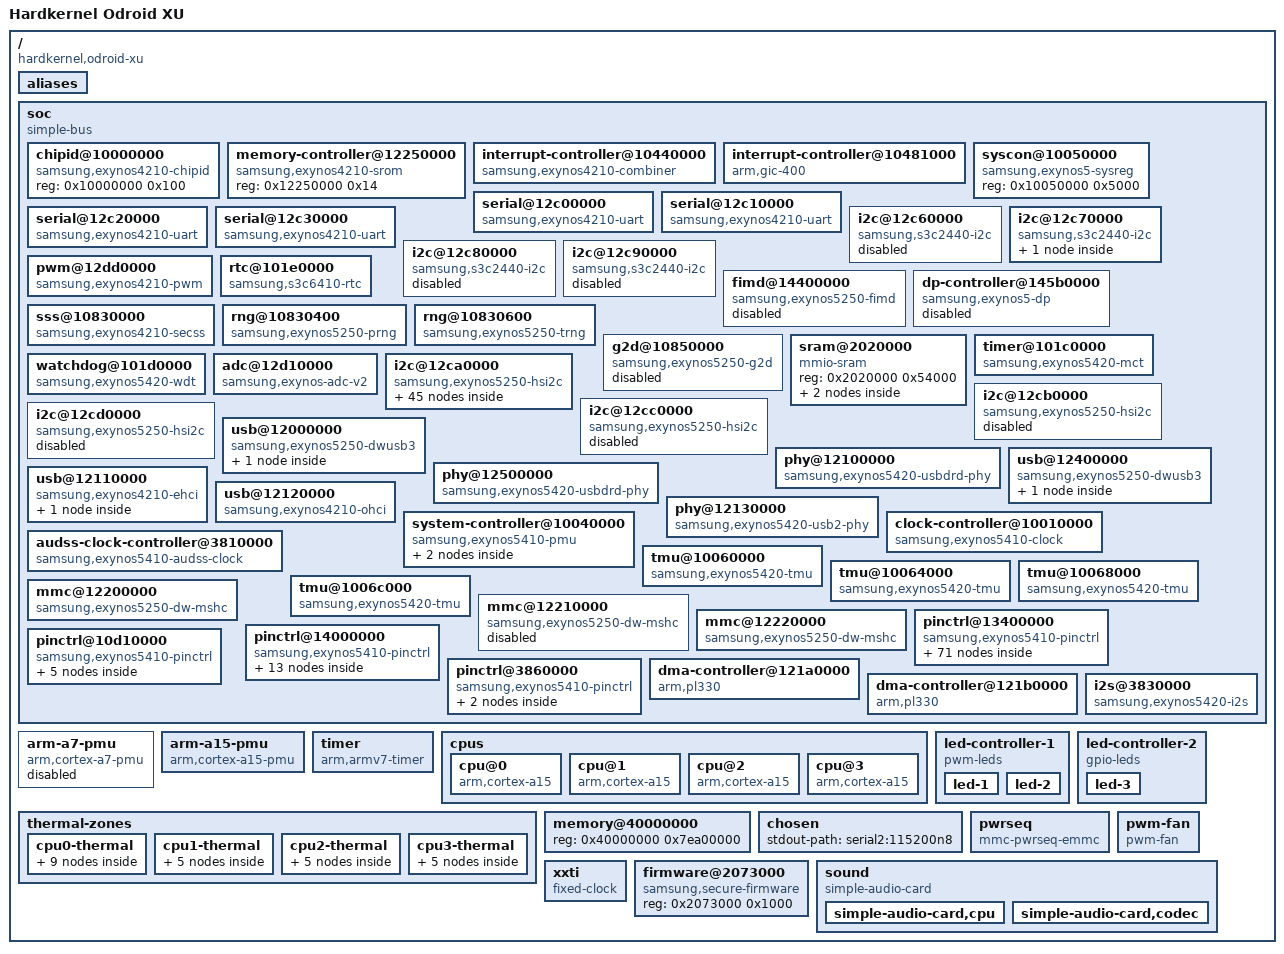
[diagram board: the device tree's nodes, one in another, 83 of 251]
/*
 * Copyright Linux Kernel Team
 *
 * SPDX-License-Identifier: GPL-2.0-only
 *
 * This file is derived from an intermediate build stage of the
 * Linux kernel. The licenses of all input files to this process
 * are compatible with GPL-2.0-only.
 */

/dts-v1/;

/ {
	interrupt-parent = <0x01>;
	#address-cells = <0x01>;
	#size-cells = <0x01>;
	compatible = "hardkernel,odroid-xu", "samsung,exynos5410", "samsung,exynos5";
	model = "Hardkernel Odroid XU";

	aliases {
		i2c0 = "/soc/i2c@12c60000";
		i2c1 = "/soc/i2c@12c70000";
		i2c2 = "/soc/i2c@12c80000";
		i2c3 = "/soc/i2c@12c90000";
		serial0 = "/soc/serial@12c00000";
		serial1 = "/soc/serial@12c10000";
		serial2 = "/soc/serial@12c20000";
		serial3 = "/soc/serial@12c30000";
		i2c4 = "/soc/i2c@12ca0000";
		i2c5 = "/soc/i2c@12cb0000";
		i2c6 = "/soc/i2c@12cc0000";
		i2c7 = "/soc/i2c@12cd0000";
		usbdrdphy0 = "/soc/phy@12100000";
		usbdrdphy1 = "/soc/phy@12500000";
		pinctrl0 = "/soc/pinctrl@13400000";
		pinctrl1 = "/soc/pinctrl@14000000";
		pinctrl2 = "/soc/pinctrl@10d10000";
		pinctrl3 = "/soc/pinctrl@3860000";
		ethernet = "/soc/usb@12110000/ethernet@2";
		mmc0 = "/soc/mmc@12200000";
		mmc1 = "/soc/mmc@12220000";
	};

	soc {
		compatible = "simple-bus";
		#address-cells = <0x01>;
		#size-cells = <0x01>;
		ranges;

		chipid@10000000 {
			compatible = "samsung,exynos4210-chipid";
			reg = <0x10000000 0x100>;
		};

		memory-controller@12250000 {
			compatible = "samsung,exynos4210-srom";
			reg = <0x12250000 0x14>;
			#address-cells = <0x02>;
			#size-cells = <0x01>;
			ranges = <0x00 0x00 0x4000000 0x20000 0x01 0x00 0x5000000 0x20000 0x02 0x00 0x6000000 0x20000 0x03 0x00 0x7000000 0x20000>;
		};

		interrupt-controller@10440000 {
			compatible = "samsung,exynos4210-combiner";
			#interrupt-cells = <0x02>;
			interrupt-controller;
			samsung,combiner-nr = <0x20>;
			reg = <0x10440000 0x1000>;
			interrupts = <0x00 0x00 0x04 0x00 0x01 0x04 0x00 0x02 0x04 0x00 0x03 0x04 0x00 0x04 0x04 0x00 0x05 0x04 0x00 0x06 0x04 0x00 0x07 0x04 0x00 0x08 0x04 0x00 0x09 0x04 0x00 0x0a 0x04 0x00 0x0b 0x04 0x00 0x0c 0x04 0x00 0x0d 0x04 0x00 0x0e 0x04 0x00 0x0f 0x04 0x00 0x10 0x04 0x00 0x11 0x04 0x00 0x12 0x04 0x00 0x13 0x04 0x00 0x14 0x04 0x00 0x15 0x04 0x00 0x16 0x04 0x00 0x17 0x04 0x00 0x18 0x04 0x00 0x19 0x04 0x00 0x1a 0x04 0x00 0x1b 0x04 0x00 0x1c 0x04 0x00 0x1d 0x04 0x00 0x1e 0x04 0x00 0x1f 0x04>;
			phandle = <0x11>;
		};

		interrupt-controller@10481000 {
			compatible = "arm,gic-400", "arm,cortex-a15-gic";
			#interrupt-cells = <0x03>;
			interrupt-controller;
			reg = <0x10481000 0x1000 0x10482000 0x2000 0x10484000 0x2000 0x10486000 0x2000>;
			interrupts = <0x01 0x09 0xf04>;
			phandle = <0x01>;
		};

		syscon@10050000 {
			compatible = "samsung,exynos5-sysreg", "syscon";
			reg = <0x10050000 0x5000>;
			phandle = <0x05>;
		};

		serial@12c00000 {
			compatible = "samsung,exynos4210-uart";
			reg = <0x12c00000 0x100>;
			interrupts = <0x00 0x33 0x04>;
			clocks = <0x02 0x101 0x02 0x80>;
			clock-names = "uart", "clk_uart_baud0";
			dmas = <0x03 0x0d 0x03 0x0e>;
			dma-names = "rx", "tx";
			status = "okay";
		};

		serial@12c10000 {
			compatible = "samsung,exynos4210-uart";
			reg = <0x12c10000 0x100>;
			interrupts = <0x00 0x34 0x04>;
			clocks = <0x02 0x102 0x02 0x81>;
			clock-names = "uart", "clk_uart_baud0";
			dmas = <0x04 0x0f 0x04 0x10>;
			dma-names = "rx", "tx";
			status = "okay";
		};

		serial@12c20000 {
			compatible = "samsung,exynos4210-uart";
			reg = <0x12c20000 0x100>;
			interrupts = <0x00 0x35 0x04>;
			clocks = <0x02 0x103 0x02 0x82>;
			clock-names = "uart", "clk_uart_baud0";
			dmas = <0x03 0x0f 0x03 0x10>;
			dma-names = "rx", "tx";
			status = "okay";
		};

		serial@12c30000 {
			compatible = "samsung,exynos4210-uart";
			reg = <0x12c30000 0x100>;
			interrupts = <0x00 0x36 0x04>;
			clocks = <0x02 0x104 0x02 0x83>;
			clock-names = "uart", "clk_uart_baud0";
			dmas = <0x04 0x11 0x04 0x12>;
			dma-names = "rx", "tx";
			status = "okay";
		};

		i2c@12c60000 {
			compatible = "samsung,s3c2440-i2c";
			reg = <0x12c60000 0x100>;
			interrupts = <0x00 0x38 0x04>;
			#address-cells = <0x01>;
			#size-cells = <0x00>;
			samsung,sysreg-phandle = <0x05>;
			status = "disabled";
			clocks = <0x02 0x105>;
			clock-names = "i2c";
			pinctrl-names = "default";
			pinctrl-0 = <0x06>;
		};

		i2c@12c70000 {
			compatible = "samsung,s3c2440-i2c";
			reg = <0x12c70000 0x100>;
			interrupts = <0x00 0x39 0x04>;
			#address-cells = <0x01>;
			#size-cells = <0x00>;
			samsung,sysreg-phandle = <0x05>;
			status = "okay";
			clocks = <0x02 0x106>;
			clock-names = "i2c";
			pinctrl-names = "default";
			pinctrl-0 = <0x07>;

			audio-codec@10 {
				compatible = "maxim,max98090";
				reg = <0x10>;
				interrupt-parent = <0x08>;
				interrupts = <0x00 0x00>;
				clocks = <0x09 0x00>;
				clock-names = "mclk";
				#sound-dai-cells = <0x00>;
				phandle = <0x50>;
			};
		};

		i2c@12c80000 {
			compatible = "samsung,s3c2440-i2c";
			reg = <0x12c80000 0x100>;
			interrupts = <0x00 0x3a 0x04>;
			#address-cells = <0x01>;
			#size-cells = <0x00>;
			samsung,sysreg-phandle = <0x05>;
			status = "disabled";
			clocks = <0x02 0x107>;
			clock-names = "i2c";
			pinctrl-names = "default";
			pinctrl-0 = <0x0a>;
		};

		i2c@12c90000 {
			compatible = "samsung,s3c2440-i2c";
			reg = <0x12c90000 0x100>;
			interrupts = <0x00 0x3b 0x04>;
			#address-cells = <0x01>;
			#size-cells = <0x00>;
			samsung,sysreg-phandle = <0x05>;
			status = "disabled";
			clocks = <0x02 0x108>;
			clock-names = "i2c";
			pinctrl-names = "default";
			pinctrl-0 = <0x0b>;
		};

		pwm@12dd0000 {
			compatible = "samsung,exynos4210-pwm";
			reg = <0x12dd0000 0x100>;
			interrupts = <0x00 0x24 0x04 0x00 0x25 0x04 0x00 0x26 0x04 0x00 0x27 0x04 0x00 0x28 0x04>;
			samsung,pwm-outputs = <0x00 0x01 0x02 0x03>;
			#pwm-cells = <0x03>;
			clocks = <0x02 0x117>;
			clock-names = "timers";
			pinctrl-0 = <0x0c 0x0d 0x0e 0x0f>;
			pinctrl-names = "default";
			status = "okay";
			phandle = <0x4b>;
		};

		rtc@101e0000 {
			compatible = "samsung,s3c6410-rtc";
			reg = <0x101e0000 0x100>;
			interrupts = <0x00 0x2b 0x04 0x00 0x2c 0x04>;
			status = "okay";
			clocks = <0x02 0x13d 0x10 0x00>;
			clock-names = "rtc", "rtc_src";
		};

		fimd@14400000 {
			compatible = "samsung,exynos5250-fimd";
			interrupt-parent = <0x11>;
			reg = <0x14400000 0x40000>;
			interrupt-names = "fifo", "vsync", "lcd_sys";
			interrupts = <0x12 0x04 0x12 0x05 0x12 0x06>;
			samsung,sysreg = <0x05>;
			status = "disabled";
		};

		dp-controller@145b0000 {
			compatible = "samsung,exynos5-dp";
			reg = <0x145b0000 0x1000>;
			interrupts = <0x0a 0x03>;
			interrupt-parent = <0x11>;
			status = "disabled";
		};

		sss@10830000 {
			compatible = "samsung,exynos4210-secss";
			reg = <0x10830000 0x300>;
			interrupts = <0x00 0x70 0x04>;
			clocks = <0x02 0x1d7>;
			clock-names = "secss";
		};

		rng@10830400 {
			compatible = "samsung,exynos5250-prng";
			reg = <0x10830400 0x200>;
			clocks = <0x02 0x1d7>;
			clock-names = "secss";
		};

		rng@10830600 {
			compatible = "samsung,exynos5250-trng";
			reg = <0x10830600 0x100>;
			clocks = <0x02 0x1d7>;
			clock-names = "secss";
		};

		g2d@10850000 {
			compatible = "samsung,exynos5250-g2d";
			reg = <0x10850000 0x1000>;
			interrupts = <0x00 0x5b 0x04>;
			status = "disabled";
		};

		sram@2020000 {
			compatible = "mmio-sram";
			reg = <0x2020000 0x54000>;
			#address-cells = <0x01>;
			#size-cells = <0x01>;
			ranges = <0x00 0x2020000 0x54000>;

			smp-sram@0 {
				compatible = "samsung,exynos4210-sysram";
				reg = <0x00 0x1000>;
			};

			smp-sram@53000 {
				compatible = "samsung,exynos4210-sysram-ns";
				reg = <0x53000 0x1000>;
			};
		};

		timer@101c0000 {
			compatible = "samsung,exynos5420-mct", "samsung,exynos4210-mct";
			reg = <0x101c0000 0xb00>;
			interrupts-extended = <0x11 0x17 0x03 0x11 0x17 0x04 0x11 0x19 0x02 0x11 0x19 0x03 0x01 0x00 0x78 0x04 0x01 0x00 0x79 0x04 0x01 0x00 0x7a 0x04 0x01 0x00 0x7b 0x04 0x01 0x00 0x80 0x04 0x01 0x00 0x81 0x04 0x01 0x00 0x82 0x04 0x01 0x00 0x83 0x04>;
			clocks = <0x12 0x02 0x13b>;
			clock-names = "fin_pll", "mct";
		};

		watchdog@101d0000 {
			compatible = "samsung,exynos5420-wdt";
			reg = <0x101d0000 0x100>;
			interrupts = <0x00 0x2a 0x04>;
			clocks = <0x02 0x13c>;
			clock-names = "watchdog";
			samsung,syscon-phandle = <0x13>;
		};

		adc@12d10000 {
			compatible = "samsung,exynos-adc-v2";
			reg = <0x12d10000 0x100>;
			interrupts = <0x00 0x6a 0x04>;
			#io-channel-cells = <0x01>;
			status = "okay";
			clocks = <0x02 0x10e>;
			clock-names = "adc";
			samsung,syscon-phandle = <0x13>;
			vdd-supply = <0x14>;
		};

		i2c@12ca0000 {
			compatible = "samsung,exynos5250-hsi2c";
			reg = <0x12ca0000 0x1000>;
			interrupts = <0x00 0x3c 0x04>;
			#address-cells = <0x01>;
			#size-cells = <0x00>;
			status = "okay";
			clocks = <0x02 0x109>;
			clock-names = "hsi2c";
			pinctrl-names = "default";
			pinctrl-0 = <0x15>;
			clock-frequency = <0x61a80>;

			usb-hub@8 {
				compatible = "smsc,usb3503";
				reg = <0x08>;
				intn-gpios = <0x16 0x07 0x00>;
				connect-gpios = <0x16 0x06 0x00>;
				reset-gpios = <0x17 0x04 0x01>;
				initial-mode = <0x01>;
				clock-names = "refclk";
				clocks = <0x13 0x00>;
				refclk-frequency = <0x16e3600>;
			};

			pmic@9 {
				compatible = "maxim,max77802";
				reg = <0x09>;
				interrupt-parent = <0x16>;
				interrupts = <0x04 0x00>;
				pinctrl-names = "default";
				pinctrl-0 = <0x18 0x19 0x1a>;
				wakeup-source;
				#clock-cells = <0x01>;
				inl1-supply = <0x1b>;
				inl2-supply = <0x1c>;
				inl3-supply = <0x1d>;
				inl4-supply = <0x1d>;
				inl5-supply = <0x1d>;
				inl6-supply = <0x1e>;
				inl7-supply = <0x1d>;
				inl10-supply = <0x1c>;
				phandle = <0x10>;

				regulators {

					BUCK1 {
						regulator-name = "vdd_mif";
						regulator-min-microvolt = "", "\f5";
						regulator-max-microvolt = <0x13d620>;
						regulator-always-on;
						regulator-boot-on;
					};

					BUCK2 {
						regulator-name = "vdd_arm";
						regulator-min-microvolt = "", "\f5";
						regulator-max-microvolt = <0x16e360>;
						regulator-always-on;
						regulator-boot-on;
					};

					BUCK3 {
						regulator-name = "vdd_int";
						regulator-min-microvolt = "", "\f5";
						regulator-max-microvolt = <0x155cc0>;
						regulator-always-on;
						regulator-boot-on;
					};

					BUCK4 {
						regulator-name = "vdd_g3d";
						regulator-min-microvolt = "", "\f5";
						regulator-max-microvolt = <0x155cc0>;
						regulator-always-on;
						regulator-boot-on;
					};

					BUCK5 {
						regulator-name = "vdd_mem";
						regulator-min-microvolt = "", "\f5";
						regulator-max-microvolt = <0x16e360>;
						regulator-always-on;
						regulator-boot-on;
						phandle = <0x1b>;
					};

					BUCK6 {
						regulator-name = "vdd_kfc";
						regulator-min-microvolt = "", "\f5";
						regulator-max-microvolt = <0x16e360>;
						regulator-always-on;
						regulator-boot-on;
					};

					BUCK7 {
						regulator-name = "buck7";
						regulator-min-microvolt = <0x13d620>;
						regulator-max-microvolt = <0x13d620>;
						regulator-always-on;
						regulator-boot-on;
						phandle = <0x1c>;
					};

					BUCK8 {
						regulator-name = "vddf_2v85";
						regulator-min-microvolt = <0x2b7cd0>;
						regulator-max-microvolt = <0x2b7cd0>;
						regulator-always-on;
						regulator-boot-on;
					};

					BUCK9 {
						regulator-name = "buck9";
						regulator-min-microvolt = <0x2dc6c0>;
						regulator-max-microvolt = <0x2dc6c0>;
						regulator-always-on;
						regulator-boot-on;
						phandle = <0x1d>;
					};

					BUCK10 {
						regulator-name = "buck10";
						regulator-min-microvolt = <0x2d0370>;
						regulator-max-microvolt = <0x2d0370>;
						regulator-always-on;
						regulator-boot-on;
						phandle = <0x1e>;
					};

					LDO1 {
						regulator-name = "vdd_alive";
						regulator-min-microvolt = <0xf4240>;
						regulator-max-microvolt = <0xf4240>;
						regulator-always-on;
					};

					LDO2 {
						regulator-name = "vddq_m1_m2";
						regulator-min-microvolt = <0x124f80>;
						regulator-max-microvolt = <0x124f80>;
						regulator-always-on;
					};

					LDO3 {
						regulator-name = "vddq_gpio";
						regulator-min-microvolt = <0x1b7740>;
						regulator-max-microvolt = <0x1b7740>;
						regulator-always-on;
					};

					LDO4 {
						regulator-name = "vddq_mmc2";
						regulator-min-microvolt = <0x1b7740>;
						regulator-max-microvolt = <0x2dc6c0>;
						regulator-always-on;
						phandle = <0x3d>;
					};

					LDO5 {
						regulator-name = "vdd18_hsic";
						regulator-min-microvolt = <0x1b7740>;
						regulator-max-microvolt = <0x1b7740>;
						regulator-always-on;
					};

					LDO6 {
						regulator-name = "vdd18_bpll";
						regulator-min-microvolt = <0x1b7740>;
						regulator-max-microvolt = <0x1b7740>;
						regulator-always-on;
					};

					LDO7 {
						regulator-name = "vddq_lcd";
						regulator-min-microvolt = <0x1b7740>;
						regulator-max-microvolt = <0x1b7740>;
						regulator-always-on;
					};

					LDO8 {
						regulator-name = "vdd10_hdmi";
						regulator-min-microvolt = <0xf4240>;
						regulator-max-microvolt = <0xf4240>;
						regulator-always-on;
					};

					LDO9 {
						regulator-name = "ldo9";
					};

					LDO10 {
						regulator-name = "vdd18_mipi";
						regulator-min-microvolt = <0x1b7740>;
						regulator-max-microvolt = <0x1b7740>;
						regulator-always-on;
						phandle = <0x14>;
					};

					LDO11 {
						regulator-name = "vddq_mmc01";
						regulator-min-microvolt = <0x1b7740>;
						regulator-max-microvolt = <0x1b7740>;
						regulator-always-on;
						phandle = <0x35>;
					};

					LDO12 {
						regulator-name = "vdd33_usb3";
						regulator-min-microvolt = <0x325aa0>;
						regulator-max-microvolt = <0x325aa0>;
						regulator-always-on;
						phandle = <0x24>;
					};

					LDO13 {
						regulator-name = "vddq_abbg0";
						regulator-min-microvolt = <0x1b7740>;
						regulator-max-microvolt = <0x1b7740>;
						regulator-always-on;
					};

					LDO14 {
						regulator-name = "vddq_abbg1";
						regulator-min-microvolt = <0x1b7740>;
						regulator-max-microvolt = <0x1b7740>;
						regulator-always-on;
					};

					LDO15 {
						regulator-name = "vdd10_usb3";
						regulator-min-microvolt = <0xf4240>;
						regulator-max-microvolt = <0xf4240>;
						regulator-always-on;
						phandle = <0x25>;
					};

					LDO17 {
						regulator-name = "cam_sensor_core";
						regulator-min-microvolt = <0x124f80>;
						regulator-max-microvolt = <0x124f80>;
					};

					LDO18 {
						regulator-name = "ldo18";
						regulator-min-microvolt = <0x1b7740>;
						regulator-max-microvolt = <0x1b7740>;
					};

					LDO19 {
						regulator-name = "ldo19";
					};

					LDO20 {
						regulator-name = "vdd_mmc0";
						regulator-min-microvolt = <0x1b7740>;
						regulator-max-microvolt = <0x1b7740>;
						phandle = <0x34>;
					};

					LDO21 {
						regulator-name = "vddf_2v8";
						regulator-min-microvolt = <0x2b7cd0>;
						regulator-max-microvolt = <0x2b7cd0>;
						phandle = <0x3c>;
					};

					LDO23 {
						regulator-name = "dp_p3v3";
						regulator-min-microvolt = <0x325aa0>;
						regulator-max-microvolt = <0x325aa0>;
						regulator-always-on;
					};

					LDO24 {
						regulator-name = "cam_af";
						regulator-min-microvolt = <0x2ab980>;
						regulator-max-microvolt = <0x2ab980>;
					};

					LDO25 {
						regulator-name = "eth_p3v3";
						regulator-min-microvolt = <0x325aa0>;
						regulator-max-microvolt = <0x325aa0>;
						regulator-always-on;
					};

					LDO26 {
						regulator-name = "usb30_extclk";
						regulator-min-microvolt = <0x325aa0>;
						regulator-max-microvolt = <0x325aa0>;
						regulator-always-on;
					};

					LDO27 {
						regulator-name = "ldo27";
					};

					LDO28 {
						regulator-name = "ldo28";
					};

					LDO29 {
						regulator-name = "ldo29";
					};

					LDO30 {
						regulator-name = "vddq_e1_e2";
						regulator-min-microvolt = <0x124f80>;
						regulator-max-microvolt = <0x124f80>;
						regulator-always-on;
					};

					LDO32 {
						regulator-name = "vs_power_meter";
						regulator-min-microvolt = <0x325aa0>;
						regulator-max-microvolt = <0x325aa0>;
					};

					LDO33 {
						regulator-name = "ldo33";
					};

					LDO34 {
						regulator-name = "ldo34";
					};

					LDO35 {
						regulator-name = "ldo35";
					};
				};
			};
		};

		i2c@12cb0000 {
			compatible = "samsung,exynos5250-hsi2c";
			reg = <0x12cb0000 0x1000>;
			interrupts = <0x00 0x3d 0x04>;
			#address-cells = <0x01>;
			#size-cells = <0x00>;
			status = "disabled";
			clocks = <0x02 0x10a>;
			clock-names = "hsi2c";
			pinctrl-names = "default";
			pinctrl-0 = <0x1f>;
		};

		i2c@12cc0000 {
			compatible = "samsung,exynos5250-hsi2c";
			reg = <0x12cc0000 0x1000>;
			interrupts = <0x00 0x3e 0x04>;
			#address-cells = <0x01>;
			#size-cells = <0x00>;
			status = "disabled";
			clocks = <0x02 0x10b>;
			clock-names = "hsi2c";
			pinctrl-names = "default";
			pinctrl-0 = <0x20>;
		};

		i2c@12cd0000 {
			compatible = "samsung,exynos5250-hsi2c";
			reg = <0x12cd0000 0x1000>;
			interrupts = <0x00 0x3f 0x04>;
			#address-cells = <0x01>;
			#size-cells = <0x00>;
			status = "disabled";
			clocks = <0x02 0x10c>;
			clock-names = "hsi2c";
			pinctrl-names = "default";
			pinctrl-0 = <0x21>;
		};

		usb@12000000 {
			compatible = "samsung,exynos5250-dwusb3";
			#address-cells = <0x01>;
			#size-cells = <0x01>;
			ranges = <0x00 0x12000000 0x10000>;
			clocks = <0x02 0x16e>;
			clock-names = "usbdrd30";
			pinctrl-names = "default";
			pinctrl-0 = <0x22 0x23>;
			vdd33-supply = <0x24>;
			vdd10-supply = <0x25>;

			usb@0 {
				compatible = "snps,dwc3";
				reg = <0x00 0x10000>;
				interrupts = <0x00 0x48 0x04>;
				phys = <0x26 0x00 0x26 0x01>;
				phy-names = "usb2-phy", "usb3-phy";
				snps,dis_u3_susphy_quirk;
				dr_mode = "peripheral";
			};
		};

		phy@12100000 {
			compatible = "samsung,exynos5420-usbdrd-phy";
			reg = <0x12100000 0x100>;
			#phy-cells = <0x01>;
			clocks = <0x02 0x16e 0x02 0x98>;
			clock-names = "phy", "ref";
			samsung,pmu-syscon = <0x13>;
			phandle = <0x26>;
		};

		usb@12400000 {
			compatible = "samsung,exynos5250-dwusb3";
			#address-cells = <0x01>;
			#size-cells = <0x01>;
			ranges = <0x00 0x12400000 0x10000>;
			clocks = <0x02 0x16f>;
			clock-names = "usbdrd30";
			pinctrl-names = "default";
			pinctrl-0 = <0x27 0x28>;
			vdd33-supply = <0x24>;
			vdd10-supply = <0x25>;

			usb@0 {
				compatible = "snps,dwc3";
				reg = <0x00 0x10000>;
				phys = <0x29 0x00 0x29 0x01>;
				phy-names = "usb2-phy", "usb3-phy";
				snps,dis_u3_susphy_quirk;
				interrupts = <0x00 0xc8 0x04>;
				dr_mode = "host";
			};
		};

		phy@12500000 {
			compatible = "samsung,exynos5420-usbdrd-phy";
			reg = <0x12500000 0x100>;
			#phy-cells = <0x01>;
			clocks = <0x02 0x16f 0x02 0x99>;
			clock-names = "phy", "ref";
			samsung,pmu-syscon = <0x13>;
			phandle = <0x29>;
		};

		usb@12110000 {
			compatible = "samsung,exynos4210-ehci";
			reg = <0x12110000 0x100>;
			interrupts = <0x00 0x47 0x04>;
			phys = <0x2a 0x00>;
			phy-names = "host";
			clocks = <0x02 0x16d>;
			clock-names = "usbhost";
			#address-cells = <0x01>;
			#size-cells = <0x00>;

			ethernet@2 {
				compatible = "usb424,9730";
				reg = <0x02>;
				local-mac-address = [00 00 00 00 00 00];
			};
		};

		usb@12120000 {
			compatible = "samsung,exynos4210-ohci";
			reg = <0x12120000 0x100>;
			interrupts = <0x00 0x47 0x04>;
			phys = <0x2a 0x00>;
			phy-names = "host";
			clocks = <0x02 0x16d>;
			clock-names = "usbhost";
		};

		phy@12130000 {
			compatible = "samsung,exynos5420-usb2-phy";
			reg = <0x12130000 0x100>;
			#phy-cells = <0x01>;
			clocks = <0x02 0x16d 0x02 0x98>;
			clock-names = "phy", "ref";
			samsung,sysreg-phandle = <0x05>;
			samsung,pmureg-phandle = <0x13>;
			phandle = <0x2a>;
		};

		system-controller@10040000 {
			compatible = "samsung,exynos5410-pmu", "syscon";
			reg = <0x10040000 0x5000>;
			clock-names = "clkout16";
			clocks = <0x12>;
			#clock-cells = <0x01>;
			phandle = <0x13>;

			syscon-poweroff {
				compatible = "syscon-poweroff";
				regmap = <0x13>;
				offset = <0x330c>;
				mask = <0x5200>;
			};

			syscon-reboot {
				compatible = "syscon-reboot";
				regmap = <0x13>;
				offset = <0x400>;
				mask = <0x01>;
			};
		};

		clock-controller@10010000 {
			compatible = "samsung,exynos5410-clock";
			reg = <0x10010000 0x30000>;
			#clock-cells = <0x01>;
			clocks = <0x12>;
			assigned-clocks = <0x02 0x07>;
			assigned-clock-rates = <0xb71b000>;
			phandle = <0x02>;
		};

		audss-clock-controller@3810000 {
			compatible = "samsung,exynos5410-audss-clock";
			reg = <0x3810000 0x0c>;
			#clock-cells = <0x01>;
			clocks = <0x12 0x02 0x07>;
			clock-names = "pll_ref", "pll_in";
			assigned-clocks = <0x2b 0x00 0x2b 0x01 0x2b 0x02 0x2b 0x03>;
			assigned-clock-parents = <0x02 0x07 0x2b 0x00>;
			assigned-clock-rates = <0x00 0x00 0x5b8d800 0x124f800>;
			phandle = <0x2b>;
		};

		tmu@10060000 {
			compatible = "samsung,exynos5420-tmu";
			reg = <0x10060000 0x100>;
			interrupts = <0x00 0x41 0x04>;
			clocks = <0x02 0x13e>;
			clock-names = "tmu_apbif";
			#thermal-sensor-cells = <0x00>;
			vtmu-supply = <0x14>;
			phandle = <0x43>;
		};

		tmu@10064000 {
			compatible = "samsung,exynos5420-tmu";
			reg = <0x10064000 0x100>;
			interrupts = <0x00 0xb7 0x04>;
			clocks = <0x02 0x13e>;
			clock-names = "tmu_apbif";
			#thermal-sensor-cells = <0x00>;
			vtmu-supply = <0x14>;
			phandle = <0x48>;
		};

		tmu@10068000 {
			compatible = "samsung,exynos5420-tmu";
			reg = <0x10068000 0x100>;
			interrupts = <0x00 0xb8 0x04>;
			clocks = <0x02 0x13e>;
			clock-names = "tmu_apbif";
			#thermal-sensor-cells = <0x00>;
			vtmu-supply = <0x14>;
			phandle = <0x49>;
		};

		tmu@1006c000 {
			compatible = "samsung,exynos5420-tmu";
			reg = <0x1006c000 0x100>;
			interrupts = <0x00 0xb9 0x04>;
			clocks = <0x02 0x13e>;
			clock-names = "tmu_apbif";
			#thermal-sensor-cells = <0x00>;
			vtmu-supply = <0x14>;
			phandle = <0x4a>;
		};

		mmc@12200000 {
			compatible = "samsung,exynos5250-dw-mshc";
			reg = <0x12200000 0x1000>;
			interrupts = <0x00 0x4b 0x04>;
			#address-cells = <0x01>;
			#size-cells = <0x00>;
			clocks = <0x02 0x15f 0x02 0x84>;
			clock-names = "biu", "ciu";
			fifo-depth = <0x80>;
			status = "okay";
			mmc-pwrseq = <0x2c>;
			cd-gpios = <0x2d 0x02 0x01>;
			card-detect-delay = <0xc8>;
			samsung,dw-mshc-ciu-div = <0x03>;
			samsung,dw-mshc-sdr-timing = <0x00 0x04>;
			samsung,dw-mshc-ddr-timing = <0x00 0x02>;
			pinctrl-names = "default";
			pinctrl-0 = <0x2e 0x2f 0x30 0x31 0x32 0x33>;
			bus-width = <0x08>;
			cap-mmc-highspeed;
			mmc-ddr-1_8v;
			mmc-hs200-1_8v;
			vmmc-supply = <0x34>;
			vqmmc-supply = <0x35>;
		};

		mmc@12210000 {
			compatible = "samsung,exynos5250-dw-mshc";
			reg = <0x12210000 0x1000>;
			interrupts = <0x00 0x4c 0x04>;
			#address-cells = <0x01>;
			#size-cells = <0x00>;
			clocks = <0x02 0x160 0x02 0x85>;
			clock-names = "biu", "ciu";
			fifo-depth = <0x80>;
			status = "disabled";
		};

		mmc@12220000 {
			compatible = "samsung,exynos5250-dw-mshc";
			reg = <0x12220000 0x1000>;
			interrupts = <0x00 0x4d 0x04>;
			#address-cells = <0x01>;
			#size-cells = <0x00>;
			clocks = <0x02 0x161 0x02 0x86>;
			clock-names = "biu", "ciu";
			fifo-depth = <0x80>;
			status = "okay";
			card-detect-delay = <0xc8>;
			samsung,dw-mshc-ciu-div = <0x03>;
			samsung,dw-mshc-sdr-timing = <0x00 0x04>;
			samsung,dw-mshc-ddr-timing = <0x00 0x02>;
			pinctrl-names = "default";
			pinctrl-0 = <0x36 0x37 0x38 0x39 0x3a 0x3b>;
			bus-width = <0x04>;
			cap-sd-highspeed;
			vmmc-supply = <0x3c>;
			vqmmc-supply = <0x3d>;
		};

		pinctrl@13400000 {
			compatible = "samsung,exynos5410-pinctrl";
			reg = <0x13400000 0x1000>;
			interrupts = <0x00 0x2d 0x04>;

			wakeup-interrupt-controller {
				compatible = "samsung,exynos4210-wakeup-eint";
				interrupt-parent = <0x01>;
				interrupts = <0x00 0x20 0x04>;
			};

			gpa0-gpio-bank {
				gpio-controller;
				#gpio-cells = <0x02>;
				interrupt-controller;
				#interrupt-cells = <0x02>;
			};

			gpa1-gpio-bank {
				gpio-controller;
				#gpio-cells = <0x02>;
				interrupt-controller;
				#interrupt-cells = <0x02>;
			};

			gpa2-gpio-bank {
				gpio-controller;
				#gpio-cells = <0x02>;
				interrupt-controller;
				#interrupt-cells = <0x02>;
			};

			gpb0-gpio-bank {
				gpio-controller;
				#gpio-cells = <0x02>;
				interrupt-controller;
				#interrupt-cells = <0x02>;
			};

			gpb1-gpio-bank {
				gpio-controller;
				#gpio-cells = <0x02>;
				interrupt-controller;
				#interrupt-cells = <0x02>;
			};

			gpb2-gpio-bank {
				gpio-controller;
				#gpio-cells = <0x02>;
				interrupt-controller;
				#interrupt-cells = <0x02>;
			};

			gpb3-gpio-bank {
				gpio-controller;
				#gpio-cells = <0x02>;
				interrupt-controller;
				#interrupt-cells = <0x02>;
			};

			gpc0-gpio-bank {
				gpio-controller;
				#gpio-cells = <0x02>;
				interrupt-controller;
				#interrupt-cells = <0x02>;
				phandle = <0x2d>;
			};

			gpc3-gpio-bank {
				gpio-controller;
				#gpio-cells = <0x02>;
				interrupt-controller;
				#interrupt-cells = <0x02>;
			};

			gpc1-gpio-bank {
				gpio-controller;
				#gpio-cells = <0x02>;
				interrupt-controller;
				#interrupt-cells = <0x02>;
			};

			gpc2-gpio-bank {
				gpio-controller;
				#gpio-cells = <0x02>;
				interrupt-controller;
				#interrupt-cells = <0x02>;
			};

			gpm5-gpio-bank {
				gpio-controller;
				#gpio-cells = <0x02>;
			};

			gpd1-gpio-bank {
				gpio-controller;
				#gpio-cells = <0x02>;
				interrupt-controller;
				#interrupt-cells = <0x02>;
				phandle = <0x4e>;
			};

			gpe0-gpio-bank {
				gpio-controller;
				#gpio-cells = <0x02>;
				interrupt-controller;
				#interrupt-cells = <0x02>;
			};

			gpe1-gpio-bank {
				gpio-controller;
				#gpio-cells = <0x02>;
				interrupt-controller;
				#interrupt-cells = <0x02>;
			};

			gpf0-gpio-bank {
				gpio-controller;
				#gpio-cells = <0x02>;
				interrupt-controller;
				#interrupt-cells = <0x02>;
			};

			gpf1-gpio-bank {
				gpio-controller;
				#gpio-cells = <0x02>;
				interrupt-controller;
				#interrupt-cells = <0x02>;
			};

			gpg0-gpio-bank {
				gpio-controller;
				#gpio-cells = <0x02>;
				interrupt-controller;
				#interrupt-cells = <0x02>;
			};

			gpg1-gpio-bank {
				gpio-controller;
				#gpio-cells = <0x02>;
				interrupt-controller;
				#interrupt-cells = <0x02>;
			};

			gpg2-gpio-bank {
				gpio-controller;
				#gpio-cells = <0x02>;
				interrupt-controller;
				#interrupt-cells = <0x02>;
			};

			gph0-gpio-bank {
				gpio-controller;
				#gpio-cells = <0x02>;
				interrupt-controller;
				#interrupt-cells = <0x02>;
			};

			gph1-gpio-bank {
				gpio-controller;
				#gpio-cells = <0x02>;
				interrupt-controller;
				#interrupt-cells = <0x02>;
			};

			gpm7-gpio-bank {
				gpio-controller;
				#gpio-cells = <0x02>;
			};

			gpy0-gpio-bank {
				gpio-controller;
				#gpio-cells = <0x02>;
			};

			gpy1-gpio-bank {
				gpio-controller;
				#gpio-cells = <0x02>;
			};

			gpy2-gpio-bank {
				gpio-controller;
				#gpio-cells = <0x02>;
			};

			gpy3-gpio-bank {
				gpio-controller;
				#gpio-cells = <0x02>;
			};

			gpy4-gpio-bank {
				gpio-controller;
				#gpio-cells = <0x02>;
			};

			gpy5-gpio-bank {
				gpio-controller;
				#gpio-cells = <0x02>;
			};

			gpy6-gpio-bank {
				gpio-controller;
				#gpio-cells = <0x02>;
			};

			gpy7-gpio-bank {
				gpio-controller;
				#gpio-cells = <0x02>;
			};

			gpx0-gpio-bank {
				gpio-controller;
				#gpio-cells = <0x02>;
				interrupt-controller;
				interrupt-parent = <0x11>;
				#interrupt-cells = <0x02>;
				interrupts = <0x17 0x00 0x18 0x00 0x19 0x00 0x19 0x01 0x1a 0x00 0x1a 0x01 0x1b 0x00 0x1b 0x01>;
				phandle = <0x16>;
			};

			gpx1-gpio-bank {
				gpio-controller;
				#gpio-cells = <0x02>;
				interrupt-controller;
				interrupt-parent = <0x11>;
				#interrupt-cells = <0x02>;
				interrupts = <0x1c 0x00 0x1c 0x01 0x1d 0x00 0x1d 0x01 0x1e 0x00 0x1e 0x01 0x1f 0x00 0x1f 0x01>;
				phandle = <0x17>;
			};

			gpx2-gpio-bank {
				gpio-controller;
				#gpio-cells = <0x02>;
				interrupt-controller;
				#interrupt-cells = <0x02>;
				phandle = <0x4c>;
			};

			gpx3-gpio-bank {
				gpio-controller;
				#gpio-cells = <0x02>;
				interrupt-controller;
				#interrupt-cells = <0x02>;
			};

			uart0-data-pins {
				samsung,pins = "gpa0-0", "gpa0-1";
				samsung,pin-function = <0x02>;
				samsung,pin-pud = <0x00>;
				samsung,pin-drv = <0x00>;
			};

			uart0-fctl-pins {
				samsung,pins = "gpa0-2", "gpa0-3";
				samsung,pin-function = <0x02>;
				samsung,pin-pud = <0x00>;
				samsung,pin-drv = <0x00>;
			};

			uart1-data-pins {
				samsung,pins = "gpa0-4", "gpa0-5";
				samsung,pin-function = <0x02>;
				samsung,pin-pud = <0x00>;
				samsung,pin-drv = <0x00>;
			};

			uart1-fctl-pins {
				samsung,pins = "gpa0-6", "gpa0-7";
				samsung,pin-function = <0x02>;
				samsung,pin-pud = <0x00>;
				samsung,pin-drv = <0x00>;
			};

			i2c2-bus-pins {
				samsung,pins = "gpa0-6", "gpa0-7";
				samsung,pin-function = <0x03>;
				samsung,pin-pud = <0x03>;
				samsung,pin-drv = <0x00>;
				phandle = <0x0a>;
			};

			uart2-data-pins {
				samsung,pins = "gpa1-0", "gpa1-1";
				samsung,pin-function = <0x02>;
				samsung,pin-pud = <0x00>;
				samsung,pin-drv = <0x00>;
			};

			uart2-fctl-pins {
				samsung,pins = "gpa1-2", "gpa1-3";
				samsung,pin-function = <0x02>;
				samsung,pin-pud = <0x00>;
				samsung,pin-drv = <0x00>;
			};

			i2c3-bus-pins {
				samsung,pins = "gpa1-2", "gpa1-3";
				samsung,pin-function = <0x03>;
				samsung,pin-pud = <0x03>;
				samsung,pin-drv = <0x00>;
				phandle = <0x0b>;
			};

			uart3-data-pins {
				samsung,pins = "gpa1-4", "gpa1-5";
				samsung,pin-function = <0x02>;
				samsung,pin-pud = <0x00>;
				samsung,pin-drv = <0x00>;
			};

			i2c4-hs-bus-pins {
				samsung,pins = "gpa2-0", "gpa2-1";
				samsung,pin-function = <0x03>;
				samsung,pin-pud = <0x03>;
				samsung,pin-drv = <0x00>;
				phandle = <0x15>;
			};

			i2c5-hs-bus-pins {
				samsung,pins = "gpa2-2", "gpa2-3";
				samsung,pin-function = <0x03>;
				samsung,pin-pud = <0x03>;
				samsung,pin-drv = <0x00>;
				phandle = <0x1f>;
			};

			i2c6-hs-bus-pins {
				samsung,pins = "gpb1-3", "gpb1-4";
				samsung,pin-function = <0x04>;
				samsung,pin-pud = <0x03>;
				samsung,pin-drv = <0x00>;
				phandle = <0x20>;
			};

			pwm0-out-pins {
				samsung,pins = "gpb2-0";
				samsung,pin-function = <0x02>;
				samsung,pin-pud = <0x00>;
				samsung,pin-drv = <0x00>;
				phandle = <0x0c>;
			};

			pwm1-out-pins {
				samsung,pins = "gpb2-1";
				samsung,pin-function = <0x02>;
				samsung,pin-pud = <0x00>;
				samsung,pin-drv = <0x00>;
				phandle = <0x0d>;
			};

			pwm2-out-pins {
				samsung,pins = "gpb2-2";
				samsung,pin-function = <0x02>;
				samsung,pin-pud = <0x00>;
				samsung,pin-drv = <0x00>;
				phandle = <0x0e>;
			};

			pwm3-out-pins {
				samsung,pins = "gpb2-3";
				samsung,pin-function = <0x02>;
				samsung,pin-pud = <0x00>;
				samsung,pin-drv = <0x00>;
				phandle = <0x0f>;
			};

			i2c7-hs-bus-pins {
				samsung,pins = "gpb2-2", "gpb2-3";
				samsung,pin-function = <0x03>;
				samsung,pin-pud = <0x03>;
				samsung,pin-drv = <0x00>;
				phandle = <0x21>;
			};

			i2c0-bus-pins {
				samsung,pins = "gpb3-0", "gpb3-1";
				samsung,pin-function = <0x02>;
				samsung,pin-pud = <0x03>;
				samsung,pin-drv = <0x00>;
				phandle = <0x06>;
			};

			i2c1-bus-pins {
				samsung,pins = "gpb3-2", "gpb3-3";
				samsung,pin-function = <0x02>;
				samsung,pin-pud = <0x03>;
				samsung,pin-drv = <0x00>;
				phandle = <0x07>;
			};

			sd0-clk-pins {
				samsung,pins = "gpc0-0";
				samsung,pin-function = <0x02>;
				samsung,pin-pud = <0x00>;
				samsung,pin-drv = <0x03>;
				phandle = <0x2e>;
			};

			sd0-cmd-pins {
				samsung,pins = "gpc0-1";
				samsung,pin-function = <0x02>;
				samsung,pin-pud = <0x00>;
				samsung,pin-drv = <0x03>;
				phandle = <0x2f>;
			};

			sd0-cd-pins {
				samsung,pins = "gpc0-2";
				samsung,pin-function = <0x02>;
				samsung,pin-pud = <0x03>;
				samsung,pin-drv = <0x03>;
				phandle = <0x33>;
			};

			sd0-bus-width1-pins {
				samsung,pins = "gpc0-3";
				samsung,pin-function = <0x02>;
				samsung,pin-pud = <0x03>;
				samsung,pin-drv = <0x03>;
				phandle = <0x30>;
			};

			sd0-bus-width4-pins {
				samsung,pins = "gpc0-4", "gpc0-5", "gpc0-6";
				samsung,pin-function = <0x02>;
				samsung,pin-pud = <0x03>;
				samsung,pin-drv = <0x03>;
				phandle = <0x31>;
			};

			sd2-clk-pins {
				samsung,pins = "gpc2-0";
				samsung,pin-function = <0x02>;
				samsung,pin-pud = <0x00>;
				samsung,pin-drv = <0x03>;
				phandle = <0x36>;
			};

			sd2-cmd-pins {
				samsung,pins = "gpc2-1";
				samsung,pin-function = <0x02>;
				samsung,pin-pud = <0x00>;
				samsung,pin-drv = <0x03>;
				phandle = <0x37>;
			};

			sd2-cd-pins {
				samsung,pins = "gpc2-2";
				samsung,pin-function = <0x02>;
				samsung,pin-pud = <0x03>;
				samsung,pin-drv = <0x03>;
				phandle = <0x38>;
			};

			sd2-bus-width1-pins {
				samsung,pins = "gpc2-3";
				samsung,pin-function = <0x02>;
				samsung,pin-pud = <0x03>;
				samsung,pin-drv = <0x03>;
				phandle = <0x39>;
			};

			sd2-bus-width4-pins {
				samsung,pins = "gpc2-4", "gpc2-5", "gpc2-6";
				samsung,pin-function = <0x02>;
				samsung,pin-pud = <0x03>;
				samsung,pin-drv = <0x03>;
				phandle = <0x3a>;
			};

			sd0-bus-width8-pins {
				samsung,pins = "gpc3-0", "gpc3-1", "gpc3-2", "gpc3-3";
				samsung,pin-function = <0x02>;
				samsung,pin-pud = <0x03>;
				samsung,pin-drv = <0x03>;
				phandle = <0x32>;
			};

			emmc-nrst-pins {
				samsung,pins = "gpd1-0";
				samsung,pin-function = <0x02>;
				samsung,pin-pud = <0x00>;
				samsung,pin-drv = <0x00>;
				phandle = <0x4d>;
			};

			sd2-wp-pins {
				samsung,pins = "gpm5-0";
				samsung,pin-function = <0x02>;
				samsung,pin-pud = <0x01>;
				samsung,pin-drv = <0x03>;
				phandle = <0x3b>;
			};

			pmic-dvs-2-pins {
				samsung,pins = "gpx0-0", "gpx0-1";
				samsung,pin-function = <0x01>;
				samsung,pin-pud = <0x00>;
				samsung,pin-drv = <0x00>;
				phandle = <0x1a>;
			};

			pmic-dvs-1-pins {
				samsung,pins = "gpx0-2";
				samsung,pin-function = <0x01>;
				samsung,pin-pud = <0x00>;
				samsung,pin-drv = <0x00>;
				samsung,pin-val = <0x01>;
				phandle = <0x19>;
			};

			max77802-irq-pins {
				samsung,pins = "gpx0-4";
				samsung,pin-function = <0x0f>;
				samsung,pin-pud = <0x00>;
				samsung,pin-drv = <0x00>;
				phandle = <0x18>;
			};
		};

		pinctrl@14000000 {
			compatible = "samsung,exynos5410-pinctrl";
			reg = <0x14000000 0x1000>;
			interrupts = <0x00 0x2e 0x04>;

			gpj0-gpio-bank {
				gpio-controller;
				#gpio-cells = <0x02>;
				interrupt-controller;
				#interrupt-cells = <0x02>;
			};

			gpj1-gpio-bank {
				gpio-controller;
				#gpio-cells = <0x02>;
				interrupt-controller;
				#interrupt-cells = <0x02>;
			};

			gpj2-gpio-bank {
				gpio-controller;
				#gpio-cells = <0x02>;
				interrupt-controller;
				#interrupt-cells = <0x02>;
			};

			gpj3-gpio-bank {
				gpio-controller;
				#gpio-cells = <0x02>;
				interrupt-controller;
				#interrupt-cells = <0x02>;
				phandle = <0x08>;
			};

			gpj4-gpio-bank {
				gpio-controller;
				#gpio-cells = <0x02>;
				interrupt-controller;
				#interrupt-cells = <0x02>;
			};

			gpk0-gpio-bank {
				gpio-controller;
				#gpio-cells = <0x02>;
				interrupt-controller;
				#interrupt-cells = <0x02>;
			};

			gpk1-gpio-bank {
				gpio-controller;
				#gpio-cells = <0x02>;
				interrupt-controller;
				#interrupt-cells = <0x02>;
			};

			gpk2-gpio-bank {
				gpio-controller;
				#gpio-cells = <0x02>;
				interrupt-controller;
				#interrupt-cells = <0x02>;
			};

			gpk3-gpio-bank {
				gpio-controller;
				#gpio-cells = <0x02>;
				interrupt-controller;
				#interrupt-cells = <0x02>;
			};

			usb3-1-oc-pins {
				samsung,pins = "gpk2-4", "gpk2-5";
				samsung,pin-function = <0x02>;
				samsung,pin-pud = <0x00>;
				samsung,pin-drv = <0x00>;
				phandle = <0x27>;
			};

			usb3-1-vbusctrl-pins {
				samsung,pins = "gpk2-6", "gpk2-7";
				samsung,pin-function = <0x02>;
				samsung,pin-pud = <0x01>;
				samsung,pin-drv = <0x00>;
				phandle = <0x28>;
			};

			usb3-0-oc-pins {
				samsung,pins = "gpk3-0", "gpk3-1";
				samsung,pin-function = <0x02>;
				samsung,pin-pud = <0x00>;
				samsung,pin-drv = <0x00>;
				phandle = <0x22>;
			};

			usb3-0-vbusctrl-pins {
				samsung,pins = "gpk3-2", "gpk3-3";
				samsung,pin-function = <0x02>;
				samsung,pin-pud = <0x01>;
				samsung,pin-drv = <0x00>;
				phandle = <0x23>;
			};
		};

		pinctrl@10d10000 {
			compatible = "samsung,exynos5410-pinctrl";
			reg = <0x10d10000 0x1000>;
			interrupts = <0x00 0x32 0x04>;

			gpv0-gpio-bank {
				gpio-controller;
				#gpio-cells = <0x02>;
				interrupt-controller;
				#interrupt-cells = <0x02>;
			};

			gpv1-gpio-bank {
				gpio-controller;
				#gpio-cells = <0x02>;
				interrupt-controller;
				#interrupt-cells = <0x02>;
			};

			gpv2-gpio-bank {
				gpio-controller;
				#gpio-cells = <0x02>;
				interrupt-controller;
				#interrupt-cells = <0x02>;
			};

			gpv3-gpio-bank {
				gpio-controller;
				#gpio-cells = <0x02>;
				interrupt-controller;
				#interrupt-cells = <0x02>;
			};

			gpv4-gpio-bank {
				gpio-controller;
				#gpio-cells = <0x02>;
				interrupt-controller;
				#interrupt-cells = <0x02>;
			};
		};

		pinctrl@3860000 {
			compatible = "samsung,exynos5410-pinctrl";
			reg = <0x3860000 0x1000>;
			interrupts = <0x00 0x2f 0x04>;

			gpz-gpio-bank {
				gpio-controller;
				#gpio-cells = <0x02>;
				interrupt-controller;
				#interrupt-cells = <0x02>;
			};

			audi2s0-bus-pins {
				samsung,pins = "gpz-0", "gpz-1", "gpz-2", "gpz-3", "gpz-4";
				samsung,pin-function = <0x02>;
				samsung,pin-pud = <0x00>;
				samsung,pin-drv = <0x00>;
				phandle = <0x3e>;
			};
		};

		dma-controller@121a0000 {
			compatible = "arm,pl330", "arm,primecell";
			reg = <0x121a0000 0x1000>;
			interrupts = <0x00 0x22 0x04>;
			clocks = <0x02 0x16a>;
			clock-names = "apb_pclk";
			#dma-cells = <0x01>;
			phandle = <0x03>;
		};

		dma-controller@121b0000 {
			compatible = "arm,pl330", "arm,primecell";
			reg = <0x121b0000 0x1000>;
			interrupts = <0x00 0x23 0x04>;
			clocks = <0x02 0x16b>;
			clock-names = "apb_pclk";
			#dma-cells = <0x01>;
			phandle = <0x04>;
		};

		i2s@3830000 {
			compatible = "samsung,exynos5420-i2s";
			reg = <0x3830000 0x100>;
			dmas = <0x03 0x0a 0x03 0x09 0x03 0x08>;
			dma-names = "tx", "rx", "tx-sec";
			clocks = <0x2b 0x06 0x2b 0x06 0x2b 0x07>;
			clock-names = "iis", "i2s_opclk0", "i2s_opclk1";
			#clock-cells = <0x01>;
			clock-output-names = "i2s_cdclk0";
			#sound-dai-cells = <0x01>;
			samsung,idma-addr = <0x3000000>;
			pinctrl-names = "default";
			pinctrl-0 = <0x3e>;
			status = "okay";
			phandle = <0x09>;
		};
	};

	arm-a7-pmu {
		compatible = "arm,cortex-a7-pmu";
		interrupt-parent = <0x01>;
		interrupts = <0x00 0xa0 0x04 0x00 0xa1 0x04 0x00 0xa2 0x04 0x00 0xa3 0x04>;
		status = "disabled";
	};

	arm-a15-pmu {
		compatible = "arm,cortex-a15-pmu";
		interrupt-parent = <0x11>;
		interrupts = <0x01 0x02 0x07 0x00 0x10 0x06 0x13 0x02>;
		status = "okay";
		interrupt-affinity = <0x3f 0x40 0x41 0x42>;
	};

	timer {
		compatible = "arm,armv7-timer";
		interrupts = <0x01 0x0d 0xf08 0x01 0x0e 0xf08 0x01 0x0b 0xf08 0x01 0x0a 0xf08>;
		clock-frequency = <0x16e3600>;
	};

	cpus {
		#address-cells = <0x01>;
		#size-cells = <0x00>;

		cpu@0 {
			device_type = "cpu";
			compatible = "arm,cortex-a15";
			reg = <0x00>;
			clock-frequency = <0x5f5e1000>;
			phandle = <0x3f>;
		};

		cpu@1 {
			device_type = "cpu";
			compatible = "arm,cortex-a15";
			reg = <0x01>;
			clock-frequency = <0x5f5e1000>;
			phandle = <0x40>;
		};

		cpu@2 {
			device_type = "cpu";
			compatible = "arm,cortex-a15";
			reg = <0x02>;
			clock-frequency = <0x5f5e1000>;
			phandle = <0x41>;
		};

		cpu@3 {
			device_type = "cpu";
			compatible = "arm,cortex-a15";
			reg = <0x03>;
			clock-frequency = <0x5f5e1000>;
			phandle = <0x42>;
		};
	};

	thermal-zones {

		cpu0-thermal {
			thermal-sensors = <0x43>;
			polling-delay-passive = <0x00>;
			polling-delay = <0x00>;

			trips {

				cpu-alert-0 {
					temperature = <0xc350>;
					hysteresis = <0x1388>;
					type = "active";
					phandle = <0x44>;
				};

				cpu-alert-1 {
					temperature = <0xea60>;
					hysteresis = <0x1388>;
					type = "active";
					phandle = <0x46>;
				};

				cpu-alert-2 {
					temperature = <0x11170>;
					hysteresis = <0x1388>;
					type = "active";
					phandle = <0x47>;
				};

				cpu-crit-0 {
					temperature = <0x1d4c0>;
					hysteresis = <0x00>;
					type = "critical";
				};
			};

			cooling-maps {

				map0 {
					trip = <0x44>;
					cooling-device = <0x45 0x00 0x01>;
				};

				map1 {
					trip = <0x46>;
					cooling-device = <0x45 0x01 0x02>;
				};

				map2 {
					trip = <0x47>;
					cooling-device = <0x45 0x02 0x03>;
				};
			};
		};

		cpu1-thermal {
			thermal-sensors = <0x48>;
			polling-delay-passive = <0x00>;
			polling-delay = <0x00>;

			trips {

				cpu-alert-0 {
					temperature = <0x14c08>;
					hysteresis = <0x2710>;
					type = "active";
				};

				cpu-alert-1 {
					temperature = <0x19258>;
					hysteresis = <0x2710>;
					type = "active";
				};

				cpu-alert-2 {
					temperature = <0x1adb0>;
					hysteresis = <0x2710>;
					type = "active";
				};

				cpu-crit-0 {
					temperature = <0x1d4c0>;
					hysteresis = <0x00>;
					type = "critical";
				};
			};
		};

		cpu2-thermal {
			thermal-sensors = <0x49>;
			polling-delay-passive = <0x00>;
			polling-delay = <0x00>;

			trips {

				cpu-alert-0 {
					temperature = <0x14c08>;
					hysteresis = <0x2710>;
					type = "active";
				};

				cpu-alert-1 {
					temperature = <0x19258>;
					hysteresis = <0x2710>;
					type = "active";
				};

				cpu-alert-2 {
					temperature = <0x1adb0>;
					hysteresis = <0x2710>;
					type = "active";
				};

				cpu-crit-0 {
					temperature = <0x1d4c0>;
					hysteresis = <0x00>;
					type = "critical";
				};
			};
		};

		cpu3-thermal {
			thermal-sensors = <0x4a>;
			polling-delay-passive = <0x00>;
			polling-delay = <0x00>;

			trips {

				cpu-alert-0 {
					temperature = <0x14c08>;
					hysteresis = <0x2710>;
					type = "active";
				};

				cpu-alert-1 {
					temperature = <0x19258>;
					hysteresis = <0x2710>;
					type = "active";
				};

				cpu-alert-2 {
					temperature = <0x1adb0>;
					hysteresis = <0x2710>;
					type = "active";
				};

				cpu-crit-0 {
					temperature = <0x1d4c0>;
					hysteresis = <0x00>;
					type = "critical";
				};
			};
		};
	};

	led-controller-1 {
		compatible = "pwm-leds";

		led-1 {
			label = "green:mmc0";
			function = "disk-activity";
			color = <0x02>;
			pwms = <0x4b 0x01 0x1e8480 0x00>;
			pwm-names = "pwm1";
			max-brightness = <0x7f>;
			linux,default-trigger = "mmc0";
		};

		led-2 {
			function = "heartbeat";
			color = <0x03>;
			pwms = <0x4b 0x02 0x1e8480 0x00>;
			pwm-names = "pwm2";
			max-brightness = <0xff>;
			linux,default-trigger = "heartbeat";
		};
	};

	led-controller-2 {
		compatible = "gpio-leds";

		led-3 {
			label = "red:microSD";
			function = "disk-activity";
			color = <0x01>;
			gpios = <0x4c 0x03 0x00>;
			default-state = "off";
			linux,default-trigger = "mmc1";
		};
	};

	memory@40000000 {
		device_type = "memory";
		reg = <0x40000000 0x7ea00000>;
	};

	chosen {
		stdout-path = "serial2:115200n8";
	};

	pwrseq {
		pinctrl-0 = <0x4d>;
		pinctrl-names = "default";
		compatible = "mmc-pwrseq-emmc";
		reset-gpios = <0x4e 0x00 0x01>;
		phandle = <0x2c>;
	};

	pwm-fan {
		compatible = "pwm-fan";
		pwms = <0x4b 0x00 0x51ec 0x00>;
		#cooling-cells = <0x02>;
		cooling-levels = <0x00 0x82 0xaa 0xe6>;
		phandle = <0x45>;
	};

	xxti {
		compatible = "fixed-clock";
		clock-frequency = <0x16e3600>;
		clock-output-names = "fin_pll";
		#clock-cells = <0x00>;
		phandle = <0x12>;
	};

	firmware@2073000 {
		compatible = "samsung,secure-firmware";
		reg = <0x2073000 0x1000>;
	};

	sound {
		compatible = "simple-audio-card";
		simple-audio-card,name = "Odroid-XU";
		simple-audio-card,widgets = "Headphone", "Headphone Jack", "Speakers", "Speakers";
		simple-audio-card,routing = "Headphone Jack", "HPL", "Headphone Jack", "HPR", "Headphone Jack", "MICBIAS", "IN1", "Headphone Jack", "Speakers", "SPKL", "Speakers", "SPKR";
		simple-audio-card,format = "i2s";
		simple-audio-card,bitclock-master = <0x4f>;
		simple-audio-card,frame-master = <0x4f>;

		simple-audio-card,cpu {
			sound-dai = <0x09 0x00>;
			system-clock-frequency = <0x124f800>;
		};

		simple-audio-card,codec {
			sound-dai = <0x50>;
			clocks = <0x09 0x00>;
			phandle = <0x4f>;
		};
	};
};
